# PIC32CZ8110CA80176 device description
Architecture: CORTEX-M7; Family: PIC32C; Series: PIC32CZCA80
Registers are 32-bit, read-write, reset 0x0 unless marked. A register's access mark holds for its fields unless they carry their own. Offsets are from the block's base; [hi:lo] are bit positions; lines under a group give offsets from that group; {n}, {i} and the like mark numbered series; 'fields as' and 'values as' point back to an identical list; <NAME> marks a mode.

## ADC — ADC Controller
Instances: ADC{n} 0x46820000 (n=0..3)
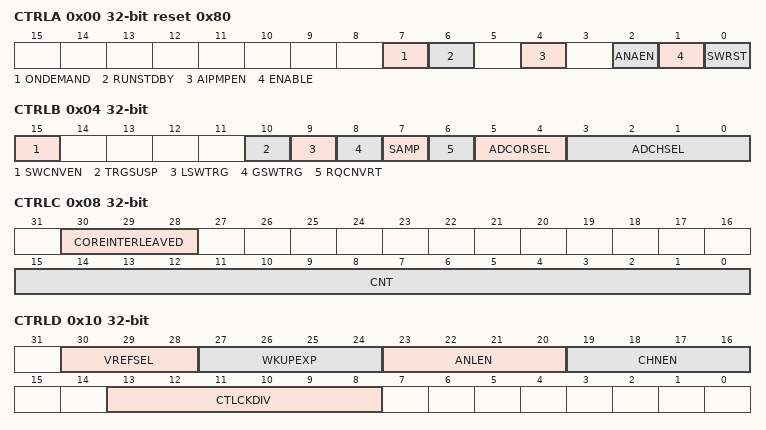
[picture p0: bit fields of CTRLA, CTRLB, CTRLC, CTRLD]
0x00 CTRLA reset 0x80 (WSYNC) — CONTROL A REGISTER
  [7] ONDEMAND — On Demand Control
  [6] RUNSTDBY — Run in Standby
  [4] AIPMPEN — Charge Pump Enable
  [2] ANAEN — Analog Enable
  [1] ENABLE — ENABLE BIT
  [0] SWRST — SOFTWARE RESET BIT
0x04 CTRLB (WSYNC) — CONTROL B REGISTER
  [15] SWCNVEN — Software Conversion Enable
  [10] TRGSUSP — Trigger Suspend
  [9] LSWTRG — Level Global Trigger
  [8] GSWTRG — Global Software Trigger
  [7] SAMP — Channel Sample
  [6] RQCNVRT — Request Channel Convert
  [5:4] ADCORSEL — Software Trigger Core Select
  [3:0] ADCHSEL — Software Trigger Channel Select
0x08 CTRLC — Control C Register
  [30:28] COREINTERLEAVED — Number of Core to Interleave Triggers
    0=INTERLEAVING_OFF; 4=INTERLEAVING_CORES_0_1 (Interleaving Cores 0 and 1); 1=INTERLEAVING_CORES_1_2 (Interleaving Cores 1 and 2); 5=INTERLEAVING_CORES_0_1_2 (Interleaving Cores 0, 1 and 2); 2=INTERLEAVING_CORES_1_2_3 (Interleaving Cores 1, 2 and 3); 3=INTERLEAVING_CORES_0_1_2_3 (Interleaving Cores 0, 1, 2 and 3)
  [15:0] CNT — Clock Divider for Synchronous Trigger
0x10 CTRLD — Control D Register
  [30:28] VREFSEL — Voltage Reference Select
    0=AVDD_AVSS (AVDD and AVSS); 1=EXTERNAL_VREFH_AVSS (External VREFH and AVSS)
  [27:24] WKUPEXP — Wakeup cycles
  [23:20] ANLEN — Analog Channel Enable
  [19:16] CHNEN — Digital Channel Enable
  [13:8] CTLCKDIV — Control Clock Divider
{0x20+0x20*i} CONFIG[{i}] (i=0..3) group
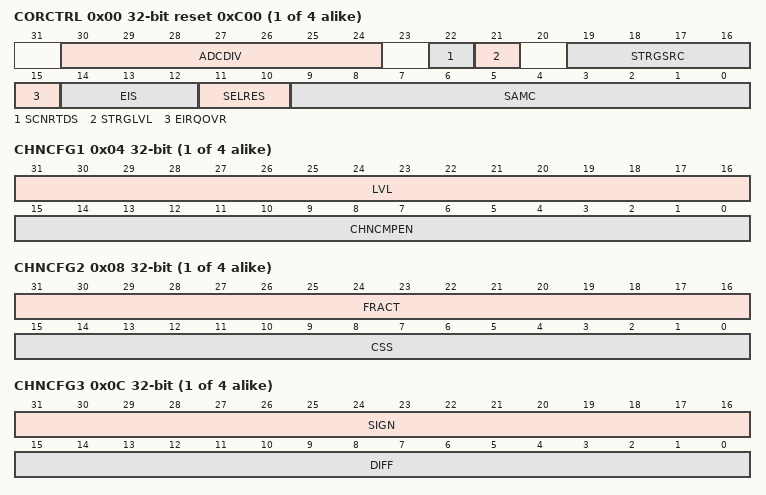
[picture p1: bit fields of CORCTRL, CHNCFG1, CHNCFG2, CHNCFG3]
  0x00 CORCTRL reset 0xC00 — SARCORE Control
    [30:24] ADCDIV — Division Ratio for SARCORE clock
    [22] SCNRTDS — SCAN Re-trigger Disable
    [21] STRGLVL — Scan Trigger Level Sensitivity
    [19:16] STRGSRC — SCAN trigger source selection
      0=NO_TRIGGER (No Trigger (NOP)); 1=GLOBAL_SOFTWARE_TRIGGER; 2=GLOBAL_LEVEL_TRIGGER (Global Level Software Trigger); 4=SYNC_TRIGGER (STRIG Synchronous Trigger); {v}=EVENT_USER{v-5} (ADC Trigger Event User {v-5}) (v=5..15)
    [15] EIRQOVR — Interrupt Type Select
    [14:12] EIS — Early Interrupt Select
    [11:10] SELRES — Selects Resolution
      0=6_BITS; 1=8_BITS; 2=10_BITS; 3=12_BITS (12 bits (default))
    [9:0] SAMC — Sample Count
  0x04 CHNCFG1 — Channel Configuration 1 (LVL/CMPEN)
    [31:16] LVL — Channel Level
    [15:0] CHNCMPEN — Channel Comparator Enable
  0x08 CHNCFG2 — Channel Configuration 2(FRACT/CSS)
    [31:16] FRACT — Channel Fractional
    [15:0] CSS — Channel SCAN Select
  0x0C CHNCFG3 — Channel Configuration3 (SIGN/DIFF)
    [31:16] SIGN — SIGN setting
    [15:0] DIFF — Differential Mode
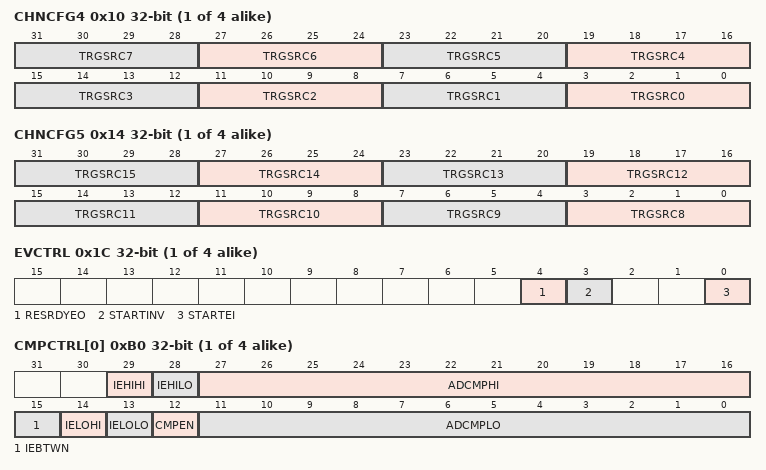
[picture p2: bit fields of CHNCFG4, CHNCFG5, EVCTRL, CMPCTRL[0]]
  0x10 CHNCFG4 — Channel Configuration 4 (TRGSRC)
    [all] fields
      0=NO_TRIGGER (No Trigger (NOP)); 1=GLOBAL_SOFTWARE_TRIGGER; 2=GLOBAL_LEVEL_TRIGGER (Global Level Software Trigger); 3=SCAN_TRIGGER (SCANTRG - Scan Trigger); 4=SYNC_TRIGGER (STRIG Synchronous Trigger); {v}=EVENT_USER{v-5} (ADC Trigger Event User {v-5}) (v=5..15)
    [4n+3:4n] TRGSRC{n} (n=0..7) — Channel {n} Trigger Source
  0x14 CHNCFG5 — Channel Configuration 5 (TRGSRC)
    [all] fields
      values as the fields of CONFIG[0].CHNCFG4
    [4n-29:4n-32] TRGSRC{n} (n=8..15) — Channel {n} Trigger Source
  0x18 CALCTRL — SARCORE Calibration Value
    [31:0] CALBITS <DEFAULT> — Calibration Values
    [31] en_ext_bias <FUSES_ADC_SARCORE_12BIT_V7A0 FUSES_ADC_SARCORE_12BIT_V7C0> — Dsiable Internal Bias Circuit
    [29:28] icmbf <FUSES_ADC_SARCORE_12BIT_V7A0 FUSES_ADC_SARCORE_12BIT_V7C0> — Bias Current Common Mode Buffer
    [27:26] icmp_2 <FUSES_ADC_SARCORE_12BIT_V7A0 FUSES_ADC_SARCORE_12BIT_V7C0> — Bias Current Stage 2
    [25:24] icmp_1 <FUSES_ADC_SARCORE_12BIT_V7A0 FUSES_ADC_SARCORE_12BIT_V7C0> — Bias Current Stage 1
    [23:22] iadc_2 <FUSES_ADC_SARCORE_12BIT_V7A0 FUSES_ADC_SARCORE_12BIT_V7C0> — Current Consumption 2
    [21:20] iadc_1 <FUSES_ADC_SARCORE_12BIT_V7A0 FUSES_ADC_SARCORE_12BIT_V7C0> — Current Consumption 1
    [15:11] tclk_div <FUSES_ADC_SARCORE_12BIT_V7A0 FUSES_ADC_SARCORE_12BIT_V7C0> — Test Clock Divider
    [10:9] t1_dly <FUSES_ADC_SARCORE_12BIT_V7A0 FUSES_ADC_SARCORE_12BIT_V7C0> — Regen Latch Delay
    [8] sel_del <FUSES_ADC_SARCORE_12BIT_V7A0 FUSES_ADC_SARCORE_12BIT_V7C0> — Scan Mode comp_out
    [7] dbg_sel <FUSES_ADC_SARCORE_12BIT_V7A0 FUSES_ADC_SARCORE_12BIT_V7C0> — Debug Bus Select
    [6] en_rdac <FUSES_ADC_SARCORE_12BIT_V7A0 FUSES_ADC_SARCORE_12BIT_V7C0> — Disable Power Cycling
    [5] dis_laz <FUSES_ADC_SARCORE_12BIT_V7A0 FUSES_ADC_SARCORE_12BIT_V7C0> — Disable auto-zeroing
    [4] dis_saz <FUSES_ADC_SARCORE_12BIT_V7A0 FUSES_ADC_SARCORE_12BIT_V7C0> — Disable auto-zeroing
    [3] dis_faz <FUSES_ADC_SARCORE_12BIT_V7A0 FUSES_ADC_SARCORE_12BIT_V7C0> — Disable auto-zeroing
    [2] en_dither <FUSES_ADC_SARCORE_12BIT_V7A0 FUSES_ADC_SARCORE_12BIT_V7C0> — Enable Dither
    [0] en_cmbf <FUSES_ADC_SARCORE_12BIT_V7A0 FUSES_ADC_SARCORE_12BIT_V7C0> — Enable Common Mode Buffer
  0x1C EVCTRL — Event Control
    [4] RESRDYEO — Result Ready Event Out
    [3] STARTINV — Start Conversion Invert
    [0] STARTEI — Start Event conversion input enable
{0xB0+4i} CMPCTRL[{i}] (i=0..3) — Comparator Control
  [29] IEHIHI — Enable VAL >= CMPHI
  [28] IEHILO — Enable VAL < CMPHI
  [27:16] ADCMPHI — High Limit of Digital Comparator
  [15] IEBTWN — Enable CMPLO <= VAL < CMPHI
  [14] IELOHI — Enable VAL >= CMPLO
  [13] IELOLO — Enable VAL < CMPLO
  [12] CMPEN — Comparator Enable
  [11:0] ADCMPLO — Low Limit of Digital Comparator
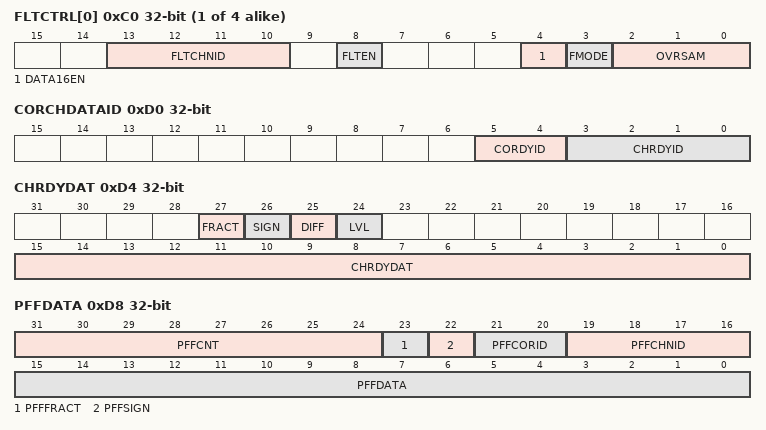
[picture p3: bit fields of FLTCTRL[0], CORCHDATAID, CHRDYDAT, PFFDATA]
{0xC0+4i} FLTCTRL[{i}] (i=0..3) — Filter Control
  [13:10] FLTCHNID — Channel ID
  [8] FLTEN — Filter Enable
  [4] DATA16EN — 16bit Averaging Mode
  [3] FMODE — Filter Mode
  [2:0] OVRSAM — Oversampling Ratio
    0=4_SAMPLES ((If FMODE is 0) 4 samples (shift sum 1 bit to right, output data is 13-bits) / (If FMODE is 1) 2 samples to be averaged); 1=16_SAMPLES ((If FMODE is 0) 16 samples (shift sum 2 bits to right, output data is 14-bits) / (If FMODE is 1) 4 samples to be averaged); 2=64_SAMPLES ((If FMODE is 0) 64 samples (shift sum 3 bits to right, output data is 15-bits) / (If FMODE is 1) 8 samples to be averaged); 3=256_SAMPLES ((If FMODE is 0) 256 samples (shift sum 4 bits to right, output data is 16-bits) / (If FMODE is 1) 16 samples to be averaged); 4=2_SAMPLES ((If FMODE is 0) 2 samples (shift sum 0 bits to right, output data is 12.1 format) / (If FMODE is 1) 32 samples to be averaged); 5=8_SAMPLES ((If FMODE is 0) 8 samples (shift sum 1 bit to right, output data is 13.1 format) / (If FMODE is 1) 64 samples to be averaged); 6=32_SAMPLES ((If FMODE is 0) 32 samples (shift sum 2 bits to right, output data is 14.1 format) / (If FMODE is 1) 128 samples to be averaged); 7=128_SAMPLES ((If FMODE is 0) 128 samples (shift sum 3 bits to right, output data is 15.1 format) / (If FMODE is 1) 256 samples to be averaged)
0xD0 CORCHDATAID — Channel Ready DATA ID
  [5:4] CORDYID — Core Read ID
  [3:0] CHRDYID — Channel Read ID
0xD4 CHRDYDAT — Channel Ready Data Register
  [27] FRACT — Fractional Setting
  [26] SIGN — Sign Setting
  [25] DIFF — Differential Setting
  [24] LVL — Level Setting
  [15:0] CHRDYDAT — Channel Output Data
0xD8 PFFDATA ro — APB FIFO Output Data
  [31:24] PFFCNT — Current Data Entries in APB FIFO
  [23] PFFFRACT — Fractional Setting from APB FIFO
  [22] PFFSIGN — Channel Sign from the APB FIFO
  [21:20] PFFCORID — Core ID from APB FIFO
  [19:16] PFFCHNID — Channel ID from APB FIFO
  [15:0] PFFDATA — SARCORE Conversion data from the APB FIFO
0xDC DMABASE — DMA Sample Base Address
  [31:0] DMABASE — DMA Sample Value Base Address
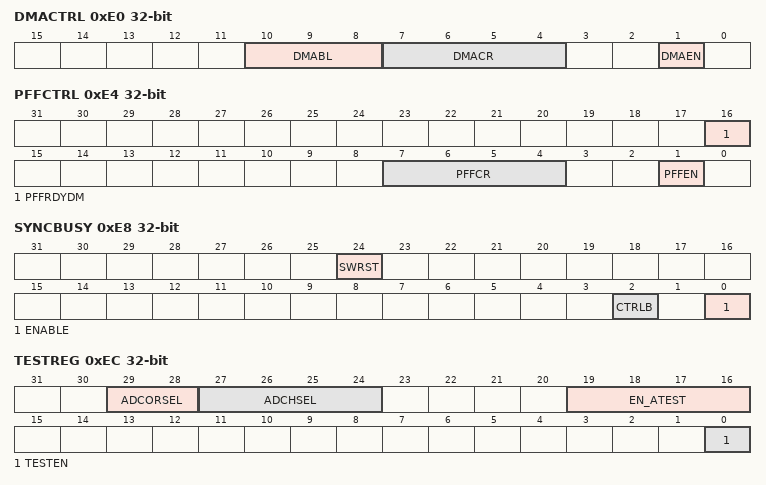
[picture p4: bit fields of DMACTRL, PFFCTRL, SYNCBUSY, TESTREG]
0xE0 DMACTRL — DMA Control Register
  [10:8] DMABL — DMA System RAM Buffer Length
  [7:4] DMACR — DMA CORE Enables
  [1] DMAEN — DMA Enable
0xE4 PFFCTRL — APB FIFO Control Register
  [16] PFFRDYDM — DMA APB FIFO Data Ready
    0=CTLINTFLAG_PFFHFUL (Selects CTLINTFLAG.PFFHFUL for the ADC DMA PFFRDY trigger signal to the DMAC); 1=CTLINTFLAG_PFFRDY (Selects CTLINTFLAG.PFFRDY for the ADC DMA PFFRDY trigger signal to the DMAC)
  [7:4] PFFCR — APB CORE FIFO Enable
  [1] PFFEN — APB FIFO Enable
0xE8 SYNCBUSY ro — CORE SYNC Busy Status Register
  [24] SWRST — Software Reset Sync Busy
  [2] CTRLB — CTRLB sync busy
  [0] ENABLE — Enable bit Sync Busy
0xEC TESTREG — Test Control Register
  [29:28] ADCORSEL — Core Select
  [27:24] ADCHSEL — Channel Select
  [19:16] EN_ATEST — Analog Test Circuitry Enables
  [0] TESTEN — Test Mode Enable
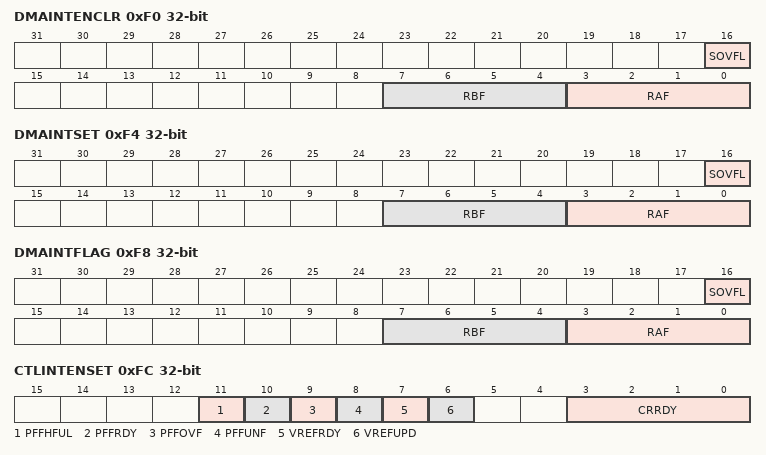
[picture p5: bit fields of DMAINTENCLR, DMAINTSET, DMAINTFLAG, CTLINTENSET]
0xF0 DMAINTENCLR (atomic clear) — DMA Interrupt Enable Clear
  [16] SOVFL — Synchonizer Overflow
  [7:4] RBF — Ram Buffer B Full
  [3:0] RAF — Ram Buffer A Full
0xF4 DMAINTSET (atomic set) — DMA Interrupt Enable Set
  fields as DMAINTENCLR
0xF8 DMAINTFLAG (atomic clear) — DMA Interrupt Flag and Status
  [16] SOVFL — Synchronizer overflow
  [7:4] RBF — Ram Buffer B Full
  [3:0] RAF — Ram Buffer A Full
0xFC CTLINTENSET (atomic set) — CORE Controller Interrupt Enable Set
  [11] PFFHFUL — APB FIFO Half Full
  [10] PFFRDY — APB FIFO Ready
  [9] PFFOVF — APB FIFO Overflow
  [8] PFFUNF — APB FIFO Underflow
  [7] VREFRDY — VREF Ready
  [6] VREFUPD — VREF update
  [3:0] CRRDY — Core Ready
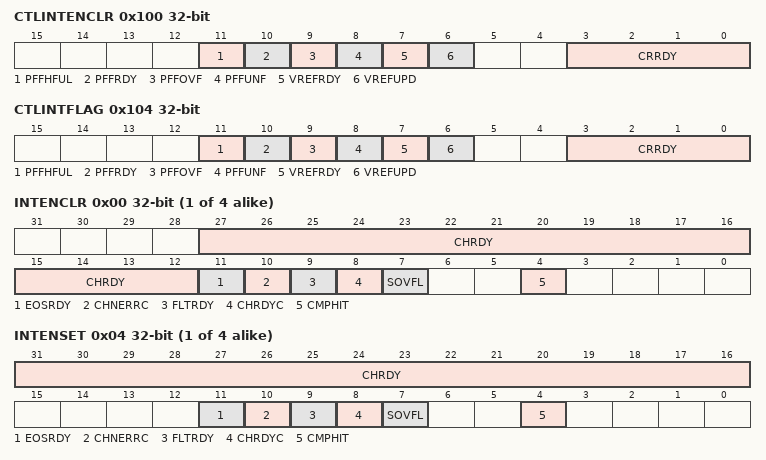
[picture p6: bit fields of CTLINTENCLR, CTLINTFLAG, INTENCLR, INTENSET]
0x100 CTLINTENCLR (atomic clear) — CORE Controller Interrupt Enable Clear
  [11] PFFHFUL — APB FIFO Half Full
  [10] PFFRDY — APB FIFO Ready
  [9] PFFOVF — APB FIFO overflow
  [8] PFFUNF — APB FIFO underflow
  [7] VREFRDY — VREF Ready
  [6] VREFUPD — VREF Update
  [3:0] CRRDY — Core Ready Disable
0x104 CTLINTFLAG (atomic clear) — CORE Controller Interrupt Flags
  [11] PFFHFUL — APB FIFO Half Full
  [10] PFFRDY — APB FIFO Ready
  [9] PFFOVF — APB FIFO overflow
  [8] PFFUNF — APB FIFO underflow
  [7] VREFRDY — VREF Ready
  [6] VREFUPD — VREF update
  [3:0] CRRDY — Core Ready
{0x120+0x10*i} INT[{i}] (i=0..3) group
  0x00 INTENCLR (atomic clear) — Interrupt Enable Clear
    [27:12] CHRDY — Channel Ready Disable
    [11] EOSRDY — Endo of Scan Disable
    [10] CHNERRC — Channel Overwrite Error Disable
    [9] FLTRDY — Filter Ready Disable
    [8] CHRDYC — Core Current Channel Disable
    [7] SOVFL — Synchonizer Overflow Disable
    [4] CMPHIT — Compare Hit Disable
  0x04 INTENSET (atomic set) — Interrupt Enable Set
    [31:16] CHRDY — Channel Ready Enable
    [11] EOSRDY — End of Scan Enable
    [10] CHNERRC — Channel Overwrite Enable
    [9] FLTRDY — Filter Ready Enable
    [8] CHRDYC — Current Channel Ready Enable
    [7] SOVFL — Synchronizer Overflow Enable
    [4] CMPHIT — Compare Hit Enable
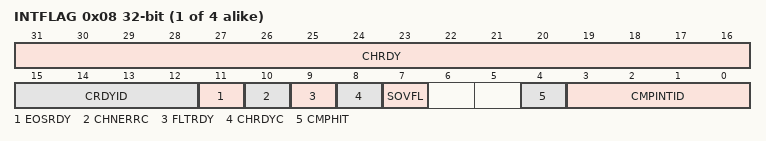
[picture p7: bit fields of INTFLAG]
  0x08 INTFLAG (atomic clear) — Interrupt Flags
    [31:16] CHRDY — Channel Ready
    [15:12] CRDYID — Channel Ready ID
    [11] EOSRDY — End of Scan Ready
    [10] CHNERRC — Channel Overwrite Error
    [9] FLTRDY — Filter Ready
    [8] CHRDYC — Current Channel Ready
    [7] SOVFL — Synchronizer Overflow
    [4] CMPHIT — Compare Hit
    [3:0] CMPINTID — Compare Channel ID
0x160 DIGTSTOUT ro — Test Debug Register
  [31:0] ADCDIGTST — Digital Debug Test port Register
0x164 TSTIDOUT — Test Degug2 Register
  [0] TSTCORID — Core Digital Test Out Read ID
0x168 DBGCTRL — Debug Control Register
  [0] DBGRUN — Debug Running State

## Notices in the file
Copyright (c) 2021 Microchip Technology Inc.
SPDX-License-Identifier: Apache-2.0
Licensed under the Apache License, Version 2.0 (the "License");
you may not use this file except in compliance with the License.
You may obtain a copy of the License at
http://www.apache.org/licenses/LICENSE-2.0
Unless required by applicable law or agreed to in writing, software
distributed under the License is distributed on an "AS IS" BASIS,
WITHOUT WARRANTIES OR CONDITIONS OF ANY KIND, either express or implied.
See the License for the specific language governing permissions and
limitations under the License.
